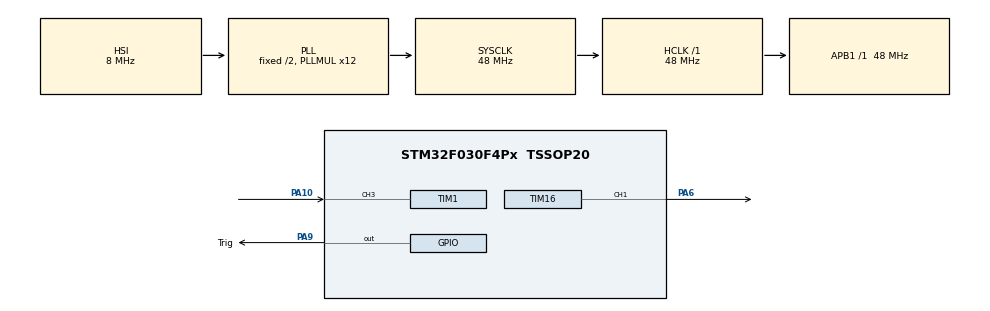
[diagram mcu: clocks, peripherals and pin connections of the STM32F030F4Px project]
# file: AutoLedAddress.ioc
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Dma.Request0=TIM16_CH1/UP
Dma.TIM16_CH1/UP.0.Direction=DMA_MEMORY_TO_PERIPH
Dma.TIM16_CH1/UP.0.Instance=DMA1_Channel3
Dma.TIM16_CH1/UP.0.MemDataAlignment=DMA_MDATAALIGN_BYTE
Dma.TIM16_CH1/UP.0.MemInc=DMA_MINC_ENABLE
Dma.TIM16_CH1/UP.0.Mode=DMA_CIRCULAR
Dma.TIM16_CH1/UP.0.PeriphDataAlignment=DMA_PDATAALIGN_HALFWORD
Dma.TIM16_CH1/UP.0.PeriphInc=DMA_PINC_DISABLE
Dma.TIM16_CH1/UP.0.Priority=DMA_PRIORITY_HIGH
Mcu.Family=STM32F0
Mcu.Name=STM32F030F4Px
Mcu.Package=TSSOP20
NVIC.DMA1_Channel2_3_IRQn=true\:0\:0\:false\:false\:true\:false\:true\:true
NVIC.TIM1_CC_IRQn=true\:0\:0\:false\:false\:true\:true\:true\:true
NVIC.TIM3_IRQn=true\:0\:0\:false\:false\:true\:true\:true\:true
PA10.Signal=S_TIM1_CH3
PA13.Mode=Serial_Wire
PA13.Signal=SYS_SWDIO
PA14.Mode=Serial_Wire
PA14.Signal=SYS_SWCLK
PA6.Signal=S_TIM16_CH1
PA9.GPIO_Label=Trig
PA9.Signal=GPIO_Output
ProjectManager.HeapSize=0x200
ProjectManager.StackSize=0x400
ProjectManager.TargetToolchain=STM32CubeIDE
RCC.AHBFreq_Value=48000000
RCC.APB1Freq_Value=48000000
RCC.APB1TimFreq_Value=48000000
RCC.HCLKFreq_Value=48000000
RCC.PLLMUL=RCC_PLL_MUL12
RCC.SYSCLKFreq_VALUE=48000000
RCC.SYSCLKSource=RCC_SYSCLKSOURCE_PLLCLK
SH.S_TIM16_CH1.0=TIM16_CH1,PWM Generation1 CH1
SH.S_TIM1_CH3.0=TIM1_CH3,Input_Capture3_from_TI3
TIM1.Channel-Input_Capture3_from_TI3=TIM_CHANNEL_3
TIM1.Channel-Input_Capture4_from_TI3_63=TIM_CHANNEL_4
TIM1.ICPolarity_CH4=TIM_INPUTCHANNELPOLARITY_FALLING
TIM1.Prescaler=48-1
TIM16.Channel=TIM_CHANNEL_1
TIM16.OCMode_PWM=TIM_OCMODE_PWM2
TIM16.Period=60-1
TIM3.Period=70-1
TIM3.Prescaler=48000-1
VP_TIM16_VS_ClockSourceINT.Mode=Enable_Timer
VP_TIM1_VS_ClockSourceINT.Mode=Internal
VP_TIM1_VS_indirect_ch3.Mode=Input_Capture4_from_TI3_63
VP_TIM3_VS_ClockSourceINT.Mode=Internal
board=custom

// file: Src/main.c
/* USER CODE BEGIN Header */
/**
  ******************************************************************************
  * @file           : main.c
  * @brief          : Main program body
  ******************************************************************************
  * @attention
  *
  * Copyright (c) 2023 STMicroelectronics.
  * All rights reserved.
  *
  * This software is licensed under terms that can be found in the LICENSE file
  * in the root directory of this software component.
  * If no LICENSE file comes with this software, it is provided AS-IS.
  *
  ******************************************************************************
  */
/* USER CODE END Header */
#include "main.h"

/* USER CODE BEGIN Includes */
#include "led.h"
/* USER CODE END Includes */

TIM_HandleTypeDef htim1;
TIM_HandleTypeDef htim3;
TIM_HandleTypeDef htim16;
DMA_HandleTypeDef hdma_tim16_ch1_up;

/* USER CODE BEGIN PV */
volatile int16_t distance_sm = 250;
uint8_t data_buffer_raw[BUFFER_SIZE] = {0,}; //RGB
data_led data_buffer;
int16_t k;
int16_t b;
/* USER CODE END PV */

void SystemClock_Config(void);
static void MX_GPIO_Init(void);
static void MX_DMA_Init(void);
static void MX_TIM16_Init(void);
static void MX_TIM1_Init(void);
static void MX_TIM3_Init(void);
/* USER CODE BEGIN PFP */
void send_trigger_signal(void); //Sending pulse to sensor
/* USER CODE END PFP */

int main(void)
{

  /* MCU Configuration--------------------------------------------------------*/

  /* Reset of all peripherals, Initializes the Flash interface and the Systick. */
  HAL_Init();

  /* Configure the system clock */
  SystemClock_Config();

  /* Initialize all configured peripherals */
  MX_GPIO_Init();
  MX_DMA_Init();
  MX_TIM16_Init();
  MX_TIM1_Init();
  MX_TIM3_Init();
  /* USER CODE BEGIN 2 */

    FLASH_OBProgramInitTypeDef ob_config;
    HAL_FLASHEx_OBGetConfig(&ob_config);
    if (ob_config.RDPLevel == OB_RDP_LEVEL0)
    {
        FLASH_OBProgramInitTypeDef set_ob_config;
        set_ob_config.OptionType = OPTIONBYTE_RDP;
        set_ob_config.RDPLevel = OB_RDP_LEVEL1;
        HAL_FLASH_Unlock();
        HAL_FLASH_OB_Unlock();
        HAL_FLASHEx_OBProgram(&set_ob_config);
        HAL_FLASH_OB_Lock();
        HAL_FLASH_Lock();
        HAL_FLASH_OB_Launch();
    }

    k = (0-(COUNT_LED-1)/2 * 10)/(DISTANCE_BACKGROUND_SM - DISTANCE_LIGHT_ON_SM);
    b = (COUNT_LED-1)/2 - k * DISTANCE_LIGHT_ON_SM / 10;
    for (int i = DELAY_COUNT_TICK; i < BUFFER_SIZE; ++i) { //empty buffer
        data_buffer_raw[i] = T0H;
    }

    HAL_Delay(1000);
    HAL_TIM_PWM_Start_DMA(&htim16,TIM_CHANNEL_1,(uint32_t *)data_buffer_raw,
                          (uint16_t)sizeof(data_buffer_raw));  //1.25us
    HAL_TIM_IC_Start_IT(&htim1, TIM_CHANNEL_3);
    HAL_TIM_IC_Start_IT(&htim1, TIM_CHANNEL_4);
    HAL_TIM_Base_Start_IT(&htim3); //1 ms
  /* USER CODE END 2 */

  /* Infinite loop */
  while (1)
  {

    /* USER CODE BEGIN 3 */

    if (distance_sm >= DISTANCE_BACKGROUND_SM) //если объект далеко
    {
        set_color_background();
    }
    else if (distance_sm < DISTANCE_BACKGROUND_SM && distance_sm > DISTANCE_LIGHT_ON_SM)  //если объект приближается
    {
        run_led();
    }
    else //если объект близко
    {
        up_light_to_max();
    }
  }
  /* USER CODE END 3 */
}

void SystemClock_Config(void)
{
  RCC_OscInitTypeDef RCC_OscInitStruct = {0};
  RCC_ClkInitTypeDef RCC_ClkInitStruct = {0};

  /** Initializes the RCC Oscillators according to the specified parameters
  * in the RCC_OscInitTypeDef structure.
  */
  RCC_OscInitStruct.OscillatorType = RCC_OSCILLATORTYPE_HSI;
  RCC_OscInitStruct.HSIState = RCC_HSI_ON;
  RCC_OscInitStruct.HSICalibrationValue = RCC_HSICALIBRATION_DEFAULT;
  RCC_OscInitStruct.PLL.PLLState = RCC_PLL_ON;
  RCC_OscInitStruct.PLL.PLLSource = RCC_PLLSOURCE_HSI;
  RCC_OscInitStruct.PLL.PLLMUL = RCC_PLL_MUL12;
  RCC_OscInitStruct.PLL.PREDIV = RCC_PREDIV_DIV1;
  if (HAL_RCC_OscConfig(&RCC_OscInitStruct) != HAL_OK)
  {
    Error_Handler();
  }

  /** Initializes the CPU, AHB and APB buses clocks
  */
  RCC_ClkInitStruct.ClockType = RCC_CLOCKTYPE_HCLK|RCC_CLOCKTYPE_SYSCLK
                              |RCC_CLOCKTYPE_PCLK1;
  RCC_ClkInitStruct.SYSCLKSource = RCC_SYSCLKSOURCE_PLLCLK;
  RCC_ClkInitStruct.AHBCLKDivider = RCC_SYSCLK_DIV1;
  RCC_ClkInitStruct.APB1CLKDivider = RCC_HCLK_DIV1;

  if (HAL_RCC_ClockConfig(&RCC_ClkInitStruct, FLASH_LATENCY_1) != HAL_OK)
  {
    Error_Handler();
  }
}

static void MX_TIM1_Init(void)
{

  TIM_ClockConfigTypeDef sClockSourceConfig = {0};
  TIM_MasterConfigTypeDef sMasterConfig = {0};
  TIM_IC_InitTypeDef sConfigIC = {0};

  htim1.Instance = TIM1;
  htim1.Init.Prescaler = 48-1;
  htim1.Init.CounterMode = TIM_COUNTERMODE_UP;
  htim1.Init.Period = 65535;
  htim1.Init.ClockDivision = TIM_CLOCKDIVISION_DIV1;
  htim1.Init.RepetitionCounter = 0;
  htim1.Init.AutoReloadPreload = TIM_AUTORELOAD_PRELOAD_DISABLE;
  if (HAL_TIM_Base_Init(&htim1) != HAL_OK)
  {
    Error_Handler();
  }
  sClockSourceConfig.ClockSource = TIM_CLOCKSOURCE_INTERNAL;
  if (HAL_TIM_ConfigClockSource(&htim1, &sClockSourceConfig) != HAL_OK)
  {
    Error_Handler();
  }
  if (HAL_TIM_IC_Init(&htim1) != HAL_OK)
  {
    Error_Handler();
  }
  sMasterConfig.MasterOutputTrigger = TIM_TRGO_RESET;
  sMasterConfig.MasterSlaveMode = TIM_MASTERSLAVEMODE_DISABLE;
  if (HAL_TIMEx_MasterConfigSynchronization(&htim1, &sMasterConfig) != HAL_OK)
  {
    Error_Handler();
  }
  sConfigIC.ICPolarity = TIM_INPUTCHANNELPOLARITY_RISING;
  sConfigIC.ICSelection = TIM_ICSELECTION_DIRECTTI;
  sConfigIC.ICPrescaler = TIM_ICPSC_DIV1;
  sConfigIC.ICFilter = 0;
  if (HAL_TIM_IC_ConfigChannel(&htim1, &sConfigIC, TIM_CHANNEL_3) != HAL_OK)
  {
    Error_Handler();
  }
  sConfigIC.ICPolarity = TIM_INPUTCHANNELPOLARITY_FALLING;
  sConfigIC.ICSelection = TIM_ICSELECTION_INDIRECTTI;
  if (HAL_TIM_IC_ConfigChannel(&htim1, &sConfigIC, TIM_CHANNEL_4) != HAL_OK)
  {
    Error_Handler();
  }

}

static void MX_TIM3_Init(void)
{

  TIM_ClockConfigTypeDef sClockSourceConfig = {0};
  TIM_MasterConfigTypeDef sMasterConfig = {0};

  htim3.Instance = TIM3;
  htim3.Init.Prescaler = 48000-1;
  htim3.Init.CounterMode = TIM_COUNTERMODE_UP;
  htim3.Init.Period = 70-1;
  htim3.Init.ClockDivision = TIM_CLOCKDIVISION_DIV1;
  htim3.Init.AutoReloadPreload = TIM_AUTORELOAD_PRELOAD_DISABLE;
  if (HAL_TIM_Base_Init(&htim3) != HAL_OK)
  {
    Error_Handler();
  }
  sClockSourceConfig.ClockSource = TIM_CLOCKSOURCE_INTERNAL;
  if (HAL_TIM_ConfigClockSource(&htim3, &sClockSourceConfig) != HAL_OK)
  {
    Error_Handler();
  }
  sMasterConfig.MasterOutputTrigger = TIM_TRGO_RESET;
  sMasterConfig.MasterSlaveMode = TIM_MASTERSLAVEMODE_DISABLE;
  if (HAL_TIMEx_MasterConfigSynchronization(&htim3, &sMasterConfig) != HAL_OK)
  {
    Error_Handler();
  }

}

static void MX_TIM16_Init(void)
{

  TIM_OC_InitTypeDef sConfigOC = {0};
  TIM_BreakDeadTimeConfigTypeDef sBreakDeadTimeConfig = {0};

  htim16.Instance = TIM16;
  htim16.Init.Prescaler = 0;
  htim16.Init.CounterMode = TIM_COUNTERMODE_UP;
  htim16.Init.Period = 60-1;
  htim16.Init.ClockDivision = TIM_CLOCKDIVISION_DIV1;
  htim16.Init.RepetitionCounter = 0;
  htim16.Init.AutoReloadPreload = TIM_AUTORELOAD_PRELOAD_DISABLE;
  if (HAL_TIM_Base_Init(&htim16) != HAL_OK)
  {
    Error_Handler();
  }
  if (HAL_TIM_PWM_Init(&htim16) != HAL_OK)
  {
    Error_Handler();
  }
  sConfigOC.OCMode = TIM_OCMODE_PWM2;
  sConfigOC.Pulse = 0;
  sConfigOC.OCPolarity = TIM_OCPOLARITY_HIGH;
  sConfigOC.OCNPolarity = TIM_OCNPOLARITY_HIGH;
  sConfigOC.OCFastMode = TIM_OCFAST_DISABLE;
  sConfigOC.OCIdleState = TIM_OCIDLESTATE_RESET;
  sConfigOC.OCNIdleState = TIM_OCNIDLESTATE_RESET;
  if (HAL_TIM_PWM_ConfigChannel(&htim16, &sConfigOC, TIM_CHANNEL_1) != HAL_OK)
  {
    Error_Handler();
  }
  sBreakDeadTimeConfig.OffStateRunMode = TIM_OSSR_DISABLE;
  sBreakDeadTimeConfig.OffStateIDLEMode = TIM_OSSI_DISABLE;
  sBreakDeadTimeConfig.LockLevel = TIM_LOCKLEVEL_OFF;
  sBreakDeadTimeConfig.DeadTime = 0;
  sBreakDeadTimeConfig.BreakState = TIM_BREAK_DISABLE;
  sBreakDeadTimeConfig.BreakPolarity = TIM_BREAKPOLARITY_HIGH;
  sBreakDeadTimeConfig.AutomaticOutput = TIM_AUTOMATICOUTPUT_DISABLE;
  if (HAL_TIMEx_ConfigBreakDeadTime(&htim16, &sBreakDeadTimeConfig) != HAL_OK)
  {
    Error_Handler();
  }
  HAL_TIM_MspPostInit(&htim16);

}

static void MX_DMA_Init(void)
{

  /* DMA controller clock enable */
  __HAL_RCC_DMA1_CLK_ENABLE();

  /* DMA interrupt init */
  /* DMA1_Channel2_3_IRQn interrupt configuration */
  HAL_NVIC_SetPriority(DMA1_Channel2_3_IRQn, 0, 0);
  HAL_NVIC_EnableIRQ(DMA1_Channel2_3_IRQn);

}

static void MX_GPIO_Init(void)
{
  GPIO_InitTypeDef GPIO_InitStruct = {0};

  /* GPIO Ports Clock Enable */
  __HAL_RCC_GPIOA_CLK_ENABLE();

  /*Configure GPIO pin Output Level */
  HAL_GPIO_WritePin(Trig_GPIO_Port, Trig_Pin, GPIO_PIN_RESET);

  /*Configure GPIO pin : Trig_Pin */
  GPIO_InitStruct.Pin = Trig_Pin;
  GPIO_InitStruct.Mode = GPIO_MODE_OUTPUT_PP;
  GPIO_InitStruct.Pull = GPIO_NOPULL;
  GPIO_InitStruct.Speed = GPIO_SPEED_FREQ_LOW;
  HAL_GPIO_Init(Trig_GPIO_Port, &GPIO_InitStruct);

}

/* USER CODE BEGIN 4 */

void send_trigger_signal(void)
{
    TIM1->CNT = 0;
    Trig_GPIO_Port->ODR |= Trig_Pin;
    TIM1->CR1 |= TIM_CR1_CEN;
    while (TIM1->CNT < 10);
    Trig_GPIO_Port->ODR &= ~Trig_Pin;
    TIM1->CR1 &= ~TIM_CR1_CEN;
    TIM1->CNT = 0;
}

void HAL_TIM_IC_CaptureCallback(TIM_HandleTypeDef *htim)
{
    if(htim->Instance == TIM1)
    {
        if(htim->Channel == HAL_TIM_ACTIVE_CHANNEL_3)
        {
            TIM1->CR1 |= TIM_CR1_CEN; // начало импульса, запускаем таймер
        }
        else if (htim->Channel == HAL_TIM_ACTIVE_CHANNEL_4) // конец импульса, измеяем длину
        {
            uint16_t counter = (uint16_t)TIM1->CNT;
            if (counter > 14500) counter = 14500;
            distance_sm += (counter / 58 - distance_sm) * 0.2; // считаем дистанцию
            TIM1->CR1 |= TIM_CR1_CEN; //запускаем таймр снова
        }
    }
}

void HAL_TIM_PeriodElapsedCallback(TIM_HandleTypeDef *htim)
{
    if (htim->Instance != htim3.Instance) return;
    send_trigger_signal();
}
/* USER CODE END 4 */

void Error_Handler(void)
{
  __disable_irq();
  while (1)
  {
  }
}
